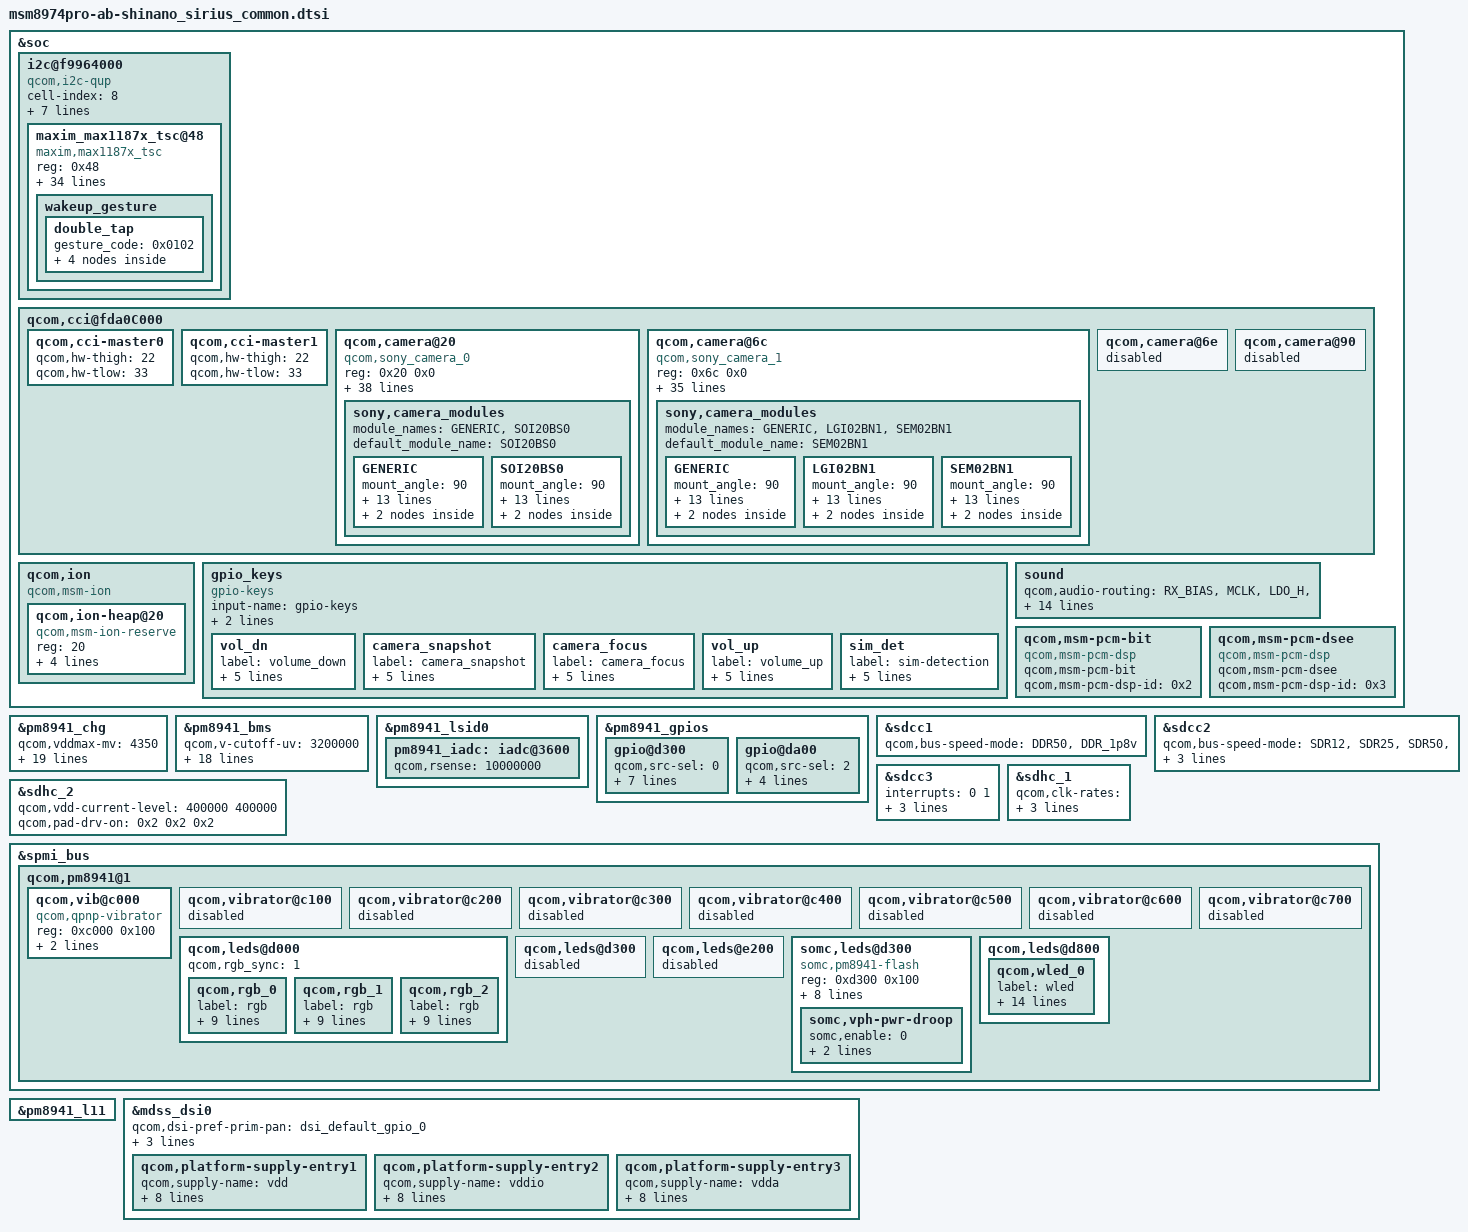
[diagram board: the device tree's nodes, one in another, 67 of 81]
/* arch/arm/boot/dts/msm8974pro-ab-shinano_sirius_common.dtsi
 *
 * Copyright (C) 2014 Sony Mobile Communications Inc.
 *
 * This program is free software; you can redistribute it and/or modify
 * it under the terms of the GNU General Public License version 2 and
 * only version 2 as published by the Free Software Foundation.
 *
 * This program is distributed in the hope that it will be useful,
 * but WITHOUT ANY WARRANTY; without even the implied warranty of
 * MERCHANTABILITY or FITNESS FOR A PARTICULAR PURPOSE.  See the
 * GNU General Public License for more details.
 */

&soc {
	/* I2C : BLSP8 */
	i2c@f9964000 {
		cell-index = <8>;
		compatible = "qcom,i2c-qup";
		reg = <0xf9964000 0x1000>;
		#address-cells = <1>;
		#size-cells = <0>;
		reg-names = "qup_phys_addr";
		interrupts = <0 102 0>;
		interrupt-names = "qup_err_intr";
		qcom,i2c-bus-freq = <355000>;
		qcom,i2c-src-freq = <50000000>;
		qcom,scl-gpio = <&msmgpio 48 0x00>;
		qcom,sda-gpio = <&msmgpio 47 0x00>;
		qcom,master-id = <84>;
		status = "ok";
		maxim_max1187x_tsc@48 {
			compatible = "maxim,max1187x_tsc";
			reg = <0x48>;
			interrupt-parent = <&msmgpio>;
			interrupts = <86 0x2>;
			touch_vdd-supply = <&pm8941_l22>;
			touch_vdd-supply_name = "touch_vdd";
			gpio_tirq = <86>;
			gpio_reset = <85>;
			reset_l2h = <1>;
			enable_resume_por = <1>;
			defaults_allow = <0>;
			default_config_id = <0>;
			default_chip_id = <0>;
			fw_name = "touch_chip_id_0x%02x_config_id_0x%%04x.bin";
			i2c_words = <128>;
			coordinate_settings = <0x4>;
			panel_margin_xl = <0>;
			lcd_x = <1080>;
			panel_margin_xh = <0>;
			panel_margin_yl = <0>;
			lcd_y = <1920>;
			panel_margin_yh = <0>;
			num_sensor_x = <20>;
			num_sensor_y = <34>;
			button_code0 = <0>;
			button_code1 = <0>;
			button_code2 = <0>;
			button_code3 = <0>;
			touch_pressure_enabled = <1>;
			touch_size_enabled = <0>;
			touch_orientation_enabled = <0>;
			glove_enabled = <0>;
			report_pen_as_finger = <1>;
			wakeup_gesture_support = <1>;
			wakeup_gesture_timeout = <2000>;
			wakeup_gesture {
				double_tap {
					gesture_code = <0x0102>;
					event_00 {
						type = <2>; /* LOG */
						message = "=== DOUBLE TAP ===";
					};
					event_01 {
						type = <1>; /* KEY */
						code = <531>; /* TOUCHPAD_ON */
						down = <1>;
					};
					event_02 {
						type = <1>; /* KEY */
						code = <531>; /* TOUCHPAD_ON */
						down = <0>;
					};
					event_03 {
						type = <99>; /* END */
					};
				};
			};
		};
	};

	qcom,cci@fda0C000 {
		qcom,cci-master0 {
			qcom,hw-thigh = <22>;
			qcom,hw-tlow = <33>;
		};

		qcom,cci-master1 {
			qcom,hw-thigh = <22>;
			qcom,hw-tlow = <33>;
		};

		qcom,camera@20 {
			compatible = "qcom,sony_camera_0";
			reg = <0x20 0x0>;
			status = "ok";
			qcom,slave-id = <0x20 0x0 0x0000>;
			qcom,csiphy-sd-index = <0>;
			qcom,csid-sd-index = <0>;
			qcom,mount-angle = <270>;
			qcom,sensor-name = "sony_camera_0";
			cam_vdig-supply = <&pm8941_l3>;
			cam_vana-supply = <&pm8941_l17>;
			cam_vio-supply = <&pm8941_lvs2>;
			cam_vaf-supply = <&pm8941_l23>;
			qcom,cam-vreg-name = "cam_vdig", "cam_vana", "cam_vio",
					     "cam_vaf";
			qcom,cam-vreg-type = <0 0 1 0>;
			qcom,cam-vreg-min-voltage = <1200000 2700000 0 2800000>;
			qcom,cam-vreg-max-voltage = <1200000 2700000 0 2800000>;
			qcom,cam-vreg-op-mode = <105000 85600 0 300000>;
			qcom,gpio-no-mux = <0>;
			gpios = <&msmgpio 15 0>,
				<&msmgpio 94 0>;
			qcom,gpio-reset = <1>;
			qcom,gpio-req-tbl-num = <0 1>;
			qcom,gpio-req-tbl-flags = <1 0>;
			qcom,gpio-req-tbl-label = "CAMIF_MCLK",
						  "CAM_RESET1";
			qcom,gpio-set-tbl-num = <1 1>;
			qcom,gpio-set-tbl-flags = <0 2>;
			qcom,gpio-set-tbl-delay = <1 1000>;
			qcom,csi-lane-assign = <0x4320>;
			qcom,csi-lane-mask = <0x1F>;
			qcom,sensor-position = <0>;
			qcom,sensor-mode = <1>;
			qcom,cci-master = <0>;
			sony,i2c_addr = <0x20>;
			sony,eeprom_addr = <0xA0>;
			sony,eeprom_type = <0>;
			sony,eeprom_max_len = <2048>;
			sony,gpio_af = <0>;
			sony,subdev_code = <0x3007>;

			sony,camera_modules {
				module_names = "GENERIC", "SOI20BS0";
				default_module_name = "SOI20BS0";

				GENERIC {
					mount_angle = <90>;
					sensor_rotation = <0>;
					sensor_facing = <0>;
					pixel_number_w = <5248>;
					pixel_number_h = <3936>;
					diagonal_len = "7.87";
					unit_cell_size = "1.20";
					min_f_number = "2.00";
					max_f_number = "2.00";
					has_focus_actuator = <1>;
					has_3a = <0>;
					pll_num = <18>;
					pll = <600 318 386 684 318 578 293 388 597 599 318 596 599 474 599 825 578 578>;
					power_off {
						commands =
								"I2C_WRITE",
								"GPIO_RESET",
								"CAM_CLK",
								"CAM_VDIG",
								"CAM_VIO",
								"CAM_VANA",
								"CAM_VAF",
								"EXIT";
						CAM_VDIG =
							<0 0xFFFFFFFF 0 1>;
						CAM_VIO = <1 0xFFFFFFFF 0 1>;
						CAM_VANA =
							<2 0xFFFFFFFF 0 1>;
						CAM_VAF = <3 0xFFFFFFFF 0 99>;
						GPIO_RESET = <5 0x0 0 1>;
						CAM_CLK = <6 0xFFFFFFFF 0 1>;
						I2C_WRITE = <7 0x0100 0 100>;
						EXIT = <8 0x0 0 0>;
					};
					power_on {
						commands =
								"CAM_VDIG",
								"CAM_VIO",
								"CAM_VANA",
								"CAM_VAF",
								"GPIO_RESET",
								"CAM_CLK",
								"EXIT";
						CAM_VDIG = <0 1200 85000 1>;
						CAM_VIO = <1 0 0 1>;
						CAM_VANA = <2 2700 103000 1>;
						CAM_VAF = <3 2800 106500 1>;
						GPIO_RESET = <5 1 0 1>;
						CAM_CLK = <6 0 0 10>;
						EXIT = <8 0x0 0 0>;
					};
				};
				SOI20BS0 {
					mount_angle = <90>;
					sensor_rotation = <0>;
					sensor_facing = <0>;
					pixel_number_w = <5248>;
					pixel_number_h = <3936>;
					diagonal_len = "7.87";
					unit_cell_size = "1.20";
					min_f_number = "2.00";
					max_f_number = "2.00";
					has_focus_actuator = <1>;
					has_3a = <0>;
					pll_num = <18>;
					pll = <600 318 386 684 318 578 293 388 597 599 318 596 599 474 599 825 578 578>;
					power_off {
						commands =
								"I2C_WRITE",
								"GPIO_RESET",
								"CAM_CLK",
								"CAM_VDIG",
								"CAM_VIO",
								"CAM_VANA",
								"CAM_VAF",
								"EXIT";
						CAM_VDIG =
							<0 0xFFFFFFFF 0 1>;
						CAM_VIO = <1 0xFFFFFFFF 0 1>;
						CAM_VANA =
							<2 0xFFFFFFFF 0 1>;
						CAM_VAF = <3 0xFFFFFFFF 0 99>;
						GPIO_RESET = <5 0x0 0 1>;
						CAM_CLK = <6 0xFFFFFFFF 0 1>;
						I2C_WRITE = <7 0x0100 0 100>;
						EXIT = <8 0x0 0 0>;
					};
					power_on {
						commands =
								"CAM_VDIG",
								"CAM_VIO",
								"CAM_VANA",
								"CAM_VAF",
								"GPIO_RESET",
								"CAM_CLK",
								"EXIT";
						CAM_VDIG = <0 1200 85000 1>;
						CAM_VIO = <1 0 0 1>;
						CAM_VANA = <2 2700 103000 1>;
						CAM_VAF = <3 2800 106500 1>;
						GPIO_RESET = <5 1 0 1>;
						CAM_CLK = <6 0 0 10>;
						EXIT = <8 0x0 0 0>;
					};
				};
			};
		};

		qcom,camera@6c {
			compatible = "qcom,sony_camera_1";
			reg = <0x6c 0x0>;
			status = "ok";
			qcom,slave-id = <0x6c 0x0000 0x0000>;
			qcom,csiphy-sd-index = <2>;
			qcom,csid-sd-index = <2>;
			qcom,mount-angle = <270>;
			qcom,sensor-name = "sony_camera_1";
			cam_vdig-supply = <&pm8941_l3>;
			cam_vana-supply = <&pm8941_l17>;
			cam_vio-supply = <&pm8941_lvs2>;
			qcom,cam-vreg-name = "cam_vdig", "cam_vana", "cam_vio";
			qcom,cam-vreg-type = <0 0 1>;
			qcom,cam-vreg-min-voltage = <1200000 2700000 0>;
			qcom,cam-vreg-max-voltage = <1200000 2700000 0>;
			qcom,cam-vreg-op-mode = <105000 85600 0>;
			qcom,gpio-no-mux = <0>;
			gpios = <&msmgpio 17 0>,
				<&msmgpio 18 0>;
			qcom,gpio-reset = <1>;
			qcom,gpio-req-tbl-num = <0 1>;
			qcom,gpio-req-tbl-flags = <1 0>;
			qcom,gpio-req-tbl-label = "CAMIF_MCLK",
						  "CAM_RESET1";
			qcom,gpio-set-tbl-num = <1 1>;
			qcom,gpio-set-tbl-flags = <0 2>;
			qcom,gpio-set-tbl-delay = <1 1000>;
			qcom,csi-lane-assign = <0x4320>;
			qcom,csi-lane-mask = <0x7>;
			qcom,sensor-position = <1>;
			qcom,sensor-mode = <1>;
			qcom,cci-master = <1>;
			sony,i2c_addr = <0x6c>;
			sony,eeprom_addr = <0xA0>;
			sony,eeprom_type = <0>;
			sony,eeprom_max_len = <1024>;
			sony,gpio_af = <0>;
			sony,subdev_code = <0x3007>;

			sony,camera_modules {
				module_names = "GENERIC", "LGI02BN1",
						"SEM02BN1";
				default_module_name = "SEM02BN1";

				GENERIC {
					mount_angle = <90>;
					sensor_rotation = <0>;
					sensor_facing = <1>;
					pixel_number_w = <1976>;
					pixel_number_h = <1200>;
					diagonal_len = "2.59";
					unit_cell_size = "1.12";
					min_f_number = "2.80";
					max_f_number = "2.80";
					has_focus_actuator = <0>;
					has_3a = <0>;
					pll_num = <18>;
					pll = <104 104 104 104 104 104 104 101 104 104 104 104 104 104 104 104 104 104>;
					power_off {
						commands =
								"I2C_WRITE",
								"GPIO_RESET",
								"CAM_CLK",
								"CAM_VANA",
								"CAM_VIO",
								"CAM_VDIG",
								"EXIT";
						CAM_VDIG =
							<0 0xFFFFFFFF 0 98>;
						CAM_VIO = <1 0xFFFFFFFF 0 1>;
						CAM_VANA =
							<2 0xFFFFFFFF 0 1>;
						GPIO_RESET = <5 0x0 0 1>;
						CAM_CLK = <6 0xFFFFFFFF 0 1>;
						I2C_WRITE = <7 0x0100 0 100>;
						EXIT = <8 0x0 0 0>;
					};
					power_on {
						commands =
								"CAM_VDIG",
								"CAM_VIO",
								"CAM_VANA",
								"GPIO_RESET",
								"CAM_CLK",
								"EXIT";
						CAM_VDIG = <0 1200 85000 1>;
						CAM_VIO = <1 0 0 1>;
						CAM_VANA = <2 2700 103000 1>;
						GPIO_RESET = <5 1 0 1>;
						CAM_CLK = <6 0 0 1>;
						EXIT = <8 0x0 0 0>;
					};
				};
				LGI02BN1 {
					mount_angle = <90>;
					sensor_rotation = <0>;
					sensor_facing = <1>;
					pixel_number_w = <1976>;
					pixel_number_h = <1200>;
					diagonal_len = "2.59";
					unit_cell_size = "1.12";
					min_f_number = "2.80";
					max_f_number = "2.80";
					has_focus_actuator = <0>;
					has_3a = <0>;
					pll_num = <18>;
					pll = <104 104 104 104 104 104 104 101 104 104 104 104 104 104 104 104 104 104>;
					power_off {
						commands =
								"I2C_WRITE",
								"GPIO_RESET",
								"CAM_CLK",
								"CAM_VANA",
								"CAM_VIO",
								"CAM_VDIG",
								"EXIT";
						CAM_VDIG =
							<0 0xFFFFFFFF 0 98>;
						CAM_VIO = <1 0xFFFFFFFF 0 1>;
						CAM_VANA =
							<2 0xFFFFFFFF 0 1>;
						GPIO_RESET = <5 0x0 0 1>;
						CAM_CLK = <6 0xFFFFFFFF 0 1>;
						I2C_WRITE = <7 0x0100 0 100>;
						EXIT = <8 0x0 0 0>;
					};
					power_on {
						commands =
								"CAM_VDIG",
								"CAM_VIO",
								"CAM_VANA",
								"GPIO_RESET",
								"CAM_CLK",
								"EXIT";
						CAM_VDIG = <0 1200 85000 1>;
						CAM_VIO = <1 0 0 1>;
						CAM_VANA = <2 2700 103000 1>;
						GPIO_RESET = <5 1 0 1>;
						CAM_CLK = <6 0 0 1>;
						EXIT = <8 0x0 0 0>;
					};
				};
				SEM02BN1 {
					mount_angle = <90>;
					sensor_rotation = <0>;
					sensor_facing = <1>;
					pixel_number_w = <1976>;
					pixel_number_h = <1200>;
					diagonal_len = "2.59";
					unit_cell_size = "1.12";
					min_f_number = "2.80";
					max_f_number = "2.80";
					has_focus_actuator = <0>;
					has_3a = <0>;
					pll_num = <18>;
					pll = <104 104 104 104 104 104 104 101 104 104 104 104 104 104 104 104 104 104>;
					power_off {
						commands =
								"I2C_WRITE",
								"GPIO_RESET",
								"CAM_CLK",
								"CAM_VANA",
								"CAM_VIO",
								"CAM_VDIG",
								"EXIT";
						CAM_VDIG =
							<0 0xFFFFFFFF 0 98>;
						CAM_VIO = <1 0xFFFFFFFF 0 1>;
						CAM_VANA =
							<2 0xFFFFFFFF 0 1>;
						GPIO_RESET = <5 0x0 0 1>;
						CAM_CLK = <6 0xFFFFFFFF 0 1>;
						I2C_WRITE = <7 0x0100 0 100>;
						EXIT = <8 0x0 0 0>;
					};
					power_on {
						commands =
								"CAM_VDIG",
								"CAM_VIO",
								"CAM_VANA",
								"GPIO_RESET",
								"CAM_CLK",
								"EXIT";
						CAM_VDIG = <0 1200 85000 1>;
						CAM_VIO = <1 0 0 1>;
						CAM_VANA = <2 2700 103000 1>;
						GPIO_RESET = <5 1 0 1>;
						CAM_CLK = <6 0 0 1>;
						EXIT = <8 0x0 0 0>;
					};
				};
			};
		};

		/* disable Qualcomm camera sensors */
		qcom,camera@6e {
			status = "disabled";
		};

		qcom,camera@90 {
			status = "disabled";
		};
	};

	qcom,ion {
		compatible = "qcom,msm-ion";

		qcom,ion-heap@20 { /* CAMERA HEAP */
			compatible = "qcom,msm-ion-reserve";
			reg = <20>;
			qcom,heap-align = <0x1000>;
			qcom,memory-reservation-type = "EBI1"; /* reserve EBI memory */
			qcom,memory-reservation-size = <0x6400000>;
			qcom,ion-heap-type = "CARVEOUT";
		};
	};

	gpio_keys {
		compatible = "gpio-keys";
		input-name = "gpio-keys";
		interrupt-parent = <&msmgpio>;
		interrupts = <9 0>;

		vol_dn {
			label = "volume_down";
			gpios = <&pm8941_gpios 2 0x1>;
			linux,input-type = <1>;
			linux,code = <114>;
			gpio-key,wakeup;
			debounce-interval = <15>;
		};

		camera_snapshot {
			label = "camera_snapshot";
			gpios = <&pm8941_gpios 3 0x1>;
			linux,input-type = <1>;
			linux,code = <0x2fe>;
			gpio-key,wakeup;
			debounce-interval = <15>;
		};

		camera_focus {
			label = "camera_focus";
			gpios = <&pm8941_gpios 4 0x1>;
			linux,input-type = <1>;
			linux,code = <0x210>;
			gpio-key,wakeup;
			debounce-interval = <15>;
		};

		vol_up {
			label = "volume_up";
			gpios = <&pm8941_gpios 5 0x1>;
			linux,input-type = <1>;
			linux,code = <115>;
			gpio-key,wakeup;
			debounce-interval = <15>;
		};

		sim_det {
			label = "sim-detection";
			gpios = <&msmgpio 9 0x0>;
			linux,input-type = <5>;
			linux,code = <7>;
			gpio-key,wakeup;
			debounce-interval = <10>;
		};
	};

	sound {
		qcom,audio-routing =
			"RX_BIAS", "MCLK",
			"LDO_H", "MCLK",
			"AMIC5", "MCLK",
			"AMIC6", "MCLK",
			"Ext Spk Bottom Pos", "LINEOUT1",
			"Ext Spk Bottom Neg", "LINEOUT3",
			"Ext Spk Top Pos", "LINEOUT2",
			"Ext Spk Top Neg", "LINEOUT4",
			"AMIC1", "MIC BIAS1 External",
			"MIC BIAS1 External", "Secondary Mic",
			"AMIC2", "MIC BIAS2 External",
			"MIC BIAS2 External", "Headset Mic",
			"MIC BIAS2 External", "ANCRight Headset Mic",
			"AMIC3", "MIC BIAS3 External",
			"MIC BIAS3 External", "ANCLeft Headset Mic",
			"AMIC4", "MIC BIAS1 External",
			"MIC BIAS1 External", "Handset Mic";
		qcom,mbhc-audio-jack-type = "5-pole-jack";
	};

	qcom,msm-pcm-bit {
		compatible = "qcom,msm-pcm-dsp";
		qcom,msm-pcm-bit;
		qcom,msm-pcm-dsp-id = <0x2>;
	};

	qcom,msm-pcm-dsee {
		compatible = "qcom,msm-pcm-dsp";
		qcom,msm-pcm-dsee;
		qcom,msm-pcm-dsp-id = <0x3>;
	};
};

&pm8941_chg {
	qcom,vddmax-mv = <4350>;
	qcom,vddsafe-mv = <4400>;
	qcom,vinmin-mv = <4200>;
	qcom,ibatmax-ma = <1600>;
	qcom,ibatterm-ma = <160>;
	qcom,ibatsafe-ma = <1600>;
	qcom,maxinput-dc-mv = <10000>;
	qcom,maxinput-usb-ma = <1500>;
	qcom,maxinput-usb-mv = <6500>;
	qcom,thermal-mitigation = <1600 1600 1100 900 700 500 300 200 100 0>;
	qcom,cool-bat-mv = <4350>;
	qcom,ibatmax-warm-ma = <900>;
	qcom,warm-bat-mv = <4200>;
	qcom,ibatmax-cool-ma = <900>;
	qcom,vbatdet-delta-mv = <70>;
	qcom,tchg-mins = <512>;
	qcom,vbatweak-mv = <3200>;
	qcom,step-thresh-soc = <101>;
	qcom,ibatmax-ma-under-step = <1600>;
};

&pm8941_bms {
	qcom,v-cutoff-uv = <3200000>;
	qcom,max-voltage-uv = <4350000>;
	qcom,r-conn-mohm = <0>;
	qcom,low-soc-calculate-soc-threshold = <15>;
	qcom,low-soc-calculate-soc-ms = <1000>;
	qcom,calculate-soc-ms = <30000>;
	qcom,chg-term-ua = <160000>;
	qcom,use-external-rsense;
	qcom,batt-type = <3>;
	qcom,use-ocv-thresholds;
	qcom,ocv-voltage-high-threshold-uv = <3830000>;
	qcom,ocv-voltage-low-threshold-uv = <3750000>;
	qcom,shutdown-soc-valid-limit = <40>;
	qcom,enable-fcc-learning;
	qcom,min-fcc-learning-soc = <20>;
	qcom,min-fcc-ocv-pc = <30>;
	qcom,min-fcc-learning-samples = <5>;
	qcom,fcc-resolution = <14>;
	qcom,clamp-soc-max-count = <2>;
};

&pm8941_lsid0 {
	pm8941_iadc: iadc@3600 {
		qcom,rsense = <10000000>;
	};
};

&pm8941_gpios {
	/* GPIO_20: LCD_DCDC_EN */
	gpio@d300 {
		qcom,src-sel = <0>;		/* GPIO */
		qcom,mode = <1>;		/* Out */
		qcom,output-type = <0>;		/* CMOS */
		qcom,vin-sel = <2>;		/* S3 */
		qcom,out-strength = <1>;	/* Low */
		qcom,invert = <0>;		/* Low */
		qcom,master-en = <1>;		/* Enable */
		somc,keep_high_at_init;
		status = "ok";
	};

	/* GPIO_27: FLASH_LED_NOW */
	gpio@da00 {
		qcom,src-sel = <2>;		/* Alternate function 1 */
		qcom,mode = <0>;		/* In */
		qcom,vin-sel = <2>;		/* S3 */
		qcom,pull = <4>;		/* PD */
		qcom,master-en = <1>;		/* Enable */
		status = "ok";
	};
};

&sdcc1 {
	qcom,bus-speed-mode = "DDR50", "DDR_1p8v";
};

&sdcc2 {
	qcom,bus-speed-mode = "SDR12", "SDR25", "SDR50", "DDR50";
	qcom,current-limit = <400>;
	qcom,pad-drv-on = <0x2 0x2 0x2>; /* 6mA, 6mA, 6mA */
};

&sdcc3 {
	interrupts = <0 1>;
	interrupt-map = <0 &intc 0 127 0
			1 &intc 0 223 0>;
	interrupt-names = "core_irq", "bam_irq";
	qcom,sup-voltages = <1800 2950>;
	somc,use-for-wifi;
	status = "ok";
};

&sdhc_1 {
	qcom,clk-rates = <400000 20000000 25000000 50000000 100000000>;
	qcom,bus-speed-mode = "DDR_1p8v";
	qcom,pad-drv-on = <0x7 0x4 0x4>; /* 16mA, 10mA, 10mA */
};

&sdhc_2 {
	qcom,vdd-current-level = <400000 400000>;
	qcom,pad-drv-on = <0x2 0x2 0x2>; /* 6mA, 6mA, 6mA */
};

&spmi_bus {
	qcom,pm8941@1 {
		qcom,vib@c000 {
			status = "okay";
			compatible = "qcom,qpnp-vibrator";
			reg = <0xc000 0x100>;
			label = "vibrator";
			qcom,qpnp-vib-vtg-level-mV = <2900>;
		};

		qcom,vibrator@c100 {
			status = "disabled";
		};

		qcom,vibrator@c200 {
			status = "disabled";
		};

		qcom,vibrator@c300 {
			status = "disabled";
		};

		qcom,vibrator@c400 {
			status = "disabled";
		};

		qcom,vibrator@c500 {
			status = "disabled";
		};

		qcom,vibrator@c600 {
			status = "disabled";
		};

		qcom,vibrator@c700 {
			status = "disabled";
		};

		qcom,leds@d000 {
			status = "okay";
			qcom,rgb_sync = <1>;

			qcom,rgb_0 {
				label = "rgb";
				linux,name = "led:rgb_red";
				qcom,mode = "pwm";
				qcom,pwm-channel = <6>;
				qcom,pwm-us = <1000>;
				qcom,pwm-max-value = <200>;
				qcom,max-current = <12>;
				qcom,default-state = "off";
				qcom,id = <3>;
				linux,default-trigger = "none";
			};

			qcom,rgb_1 {
				label = "rgb";
				linux,name = "led:rgb_green";
				qcom,mode = "pwm";
				qcom,pwm-channel = <5>;
				qcom,pwm-us = <1000>;
				qcom,pwm-max-value = <511>;
				qcom,max-current = <12>;
				qcom,default-state = "off";
				qcom,id = <4>;
				linux,default-trigger = "none";
			};

			qcom,rgb_2 {
				label = "rgb";
				linux,name = "led:rgb_blue";
				qcom,mode = "pwm";
				qcom,pwm-channel = <4>;
				qcom,pwm-us = <1000>;
				qcom,pwm-max-value = <341>;
				qcom,max-current = <12>;
				qcom,default-state = "off";
				qcom,id = <5>;
				linux,default-trigger = "none";
			};
		};

		qcom,leds@d300 {
			status = "disabled";
		};

		qcom,leds@e200 {
			status = "disabled";
		};

		somc,leds@d300 {
			status = "okay";
			compatible = "somc,pm8941-flash";
			reg = <0xd300 0x100>;
			label = "flash";
			torch-supply = <&pm8941_boost>;
			flash-supply = <&pm8941_chg_boost>;
			somc,headroom = <2>;
			somc,clamp-curr-mA = <13>;
			somc,startup-dly = <3>;
			somc,hw-strobe-config = <3>;
			somc,mask-enable = <1>;
			somc,vph-pwr-droop {
				somc,enable = <0>;
				somc,threshold = <0>;
				somc,debounce-time = <2>;
			};
		};

		qcom,leds@d800 {
			status = "okay";
			qcom,wled_0 {
				label = "wled";
				linux,name = "wled:backlight";
				linux,default-trigger = "bkl-trigger";
				qcom,cs-out-en = <1>;
				qcom,cabc-en = <0>;
				qcom,op-fdbck = <0>;
				qcom,default-state = "on";
				qcom,max-current = <20>;
				qcom,ctrl-delay-us = <0>;
				qcom,boost-curr-lim = <3>;
				qcom,cp-sel = <0>;
				qcom,switch-freq = <2>;
				qcom,ovp-val = <2>;
				qcom,num-strings = <2>;
				qcom,id = <0>;
			};
		};
	};
};

/* Regulator config */
&pm8941_l11 {
	status = "ok";
};

&mdss_dsi0 {
	qcom,dsi-pref-prim-pan = <&dsi_default_gpio_0>;
	vdd-supply = <&pm8941_lvs3>;
	qcom,platform-enable-gpio = <&pm8941_gpios 20 0>;
	qcom,platform-lane-config = [];
	qcom,platform-supply-entry1 {
			qcom,supply-name = "vdd";
			qcom,supply-min-voltage = <0>;
			qcom,supply-max-voltage = <0>;
			qcom,supply-enable-load = <100000>;
			qcom,supply-disable-load = <100>;
			qcom,supply-pre-on-sleep = <0>;
			qcom,supply-post-on-sleep = <0>;
			qcom,supply-pre-off-sleep = <0>;
			qcom,supply-post-off-sleep = <0>;
	};
	qcom,platform-supply-entry2 {
			qcom,supply-name = "vddio";
			qcom,supply-min-voltage = <1800000>;
			qcom,supply-max-voltage = <1800000>;
			qcom,supply-enable-load = <100000>;
			qcom,supply-disable-load = <100>;
			qcom,supply-pre-on-sleep = <0>;
			qcom,supply-post-on-sleep = <0>;
			qcom,supply-pre-off-sleep = <0>;
			qcom,supply-post-off-sleep = <0>;
	};
	qcom,platform-supply-entry3 {
			qcom,supply-name = "vdda";
			qcom,supply-min-voltage = <1200000>;
			qcom,supply-max-voltage = <1200000>;
			qcom,supply-enable-load = <100000>;
			qcom,supply-disable-load = <100>;
			qcom,supply-pre-on-sleep = <0>;
			qcom,supply-post-on-sleep = <0>;
			qcom,supply-pre-off-sleep = <0>;
			qcom,supply-post-off-sleep = <0>;
	};
};
